# earlgrey register map
Vendor: lowRISC OpenTitan; File version: snapshot-20191101-1-518-g9293d546-dirty
# OpenTitan ![OpenTitan logo](doc/opentitan-logo.png) ## About the project [OpenTitan](https://opentitan.org) is an open source silicon Root of Trust (RoT) project. OpenTitan will make the silicon RoT design and implementation more transparent, trustworthy, and secure for enterprises, platform providers, and chip manufacturers. OpenTitan is administered by [lowRISC CIC](https://www.lowrisc.org) as a collaborative project to produce high quality, open IP for instantiation as a full-featured product. See the the [OpenTitan site](https://opentitan.org/) and [OpenTitan docs](https://docs.opentitan.org) for more information about the project. ## About this repository This repository contains hardware, software and utilities written as part of the OpenTitan project. It is structured as monolithic repository, or "monorepo", where all components live in one repository. It exists to enable collaboration across partners participating in the OpenTitan project. ## Documentation The project contains comprehensive documentation of all IPs and tools. You can either access it [online](https://docs.opentitan.org/) or build it locally by following the steps below. 1. Ensure that you have the required Python modules installed (to be executed in the repository root): ```command $ sudo apt install curl python3 python3-pip $ pip3 install --user -r python-requirements.txt ``` 2. Execute the build script: ```command $ ./util/build_docs.py --preview ``` This compiles the documentation into `./build/d
CPU: RISCV 0, little endian, MPU, no FPU, 0 interrupt priority bits
Registers are 32-bit, read-write, reset 0x0 unless marked. A register's access mark holds for its fields unless they carry their own. Offsets are from the block's base; lines under a group give offsets from that group; [hi:lo] are bit positions; {n}, {i} and the like mark numbered series; 'fields as' and 'values as' point back to an identical list; <NAME> marks a mode.

## Memory map
0x40000000 uart
0x40010000 gpio
0x40020000 spi_device
0x40030000 flash_ctrl
0x40070000 pinmux
0x40080000 rv_timer
0x40090000 rv_plic
0x40110000 aes
0x40120000 hmac
0x40130000 alert_handler
0x40140000 nmi_gen

## Interrupts
0 classa (alert_handler)
0 esc0 (nmi_gen)
0 gpio
0 hmac_done (hmac)
0 prog_empty (flash_ctrl)
0 rxf (spi_device)
0 timer_expired_0_0 (rv_timer)
0 tx_watermark (uart)
1 classb (alert_handler)
1 esc1 (nmi_gen)
1 fifo_full (hmac)
1 prog_lvl (flash_ctrl)
1 rx_watermark (uart)
1 rxlvl (spi_device)
2 classc (alert_handler)
2 esc2 (nmi_gen)
2 hmac_err (hmac)
2 rd_full (flash_ctrl)
2 tx_empty (uart)
2 txlvl (spi_device)
3 classd (alert_handler)
3 esc3 (nmi_gen)
3 rd_lvl (flash_ctrl)
3 rx_overflow (uart)
3 rxerr (spi_device)
4 op_done (flash_ctrl)
4 rx_frame_err (uart)
4 rxoverflow (spi_device)
5 op_error (flash_ctrl)
5 rx_break_err (uart)
5 txunderflow (spi_device)
6 rx_timeout (uart)
7 rx_parity_err (uart)

## rv_timer
Base 0x40080000
0x00 CTRL — Control register
  [0] active0 — If 1, timer operates for TIMER0
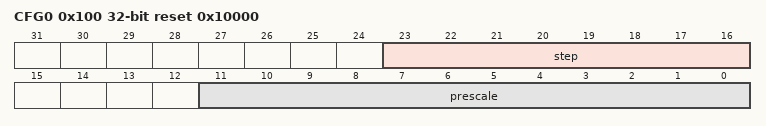
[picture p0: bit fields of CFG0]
0x100 CFG0 reset 0x10000 — Configuration for Hart 0
  [23:16] step — Incremental value for each tick
  [11:0] prescale — Prescaler to generate tick
0x104 TIMER_V_LOWER0 — Timer value Lower
  [31:0] v — Timer value [31:0]
0x108 TIMER_V_UPPER0 — Timer value Upper
  [31:0] v — Timer value [63:32]
0x10C COMPARE_LOWER0_0 reset 0xFFFFFFFF — Timer value Lower
  [31:0] v — Timer compare value [31:0]
0x110 COMPARE_UPPER0_0 reset 0xFFFFFFFF — Timer value Upper
  [31:0] v — Timer compare value [63:32]
0x114 INTR_ENABLE0 — Interrupt Enable
  [0] IE0 — Interrupt Enable for timer for TIMER0
0x118 INTR_STATE0 write-1-clears — Interrupt Status
  [0] IS0 write-1-clears — Interrupt status for timer for TIMER0
0x11C INTR_TEST0 wo reset not defined — Interrupt test register
  [0] T0 — Interrupt test for timer for TIMER0

## rv_plic
Base 0x40090000
0x00 IP group — Interrupt Pending
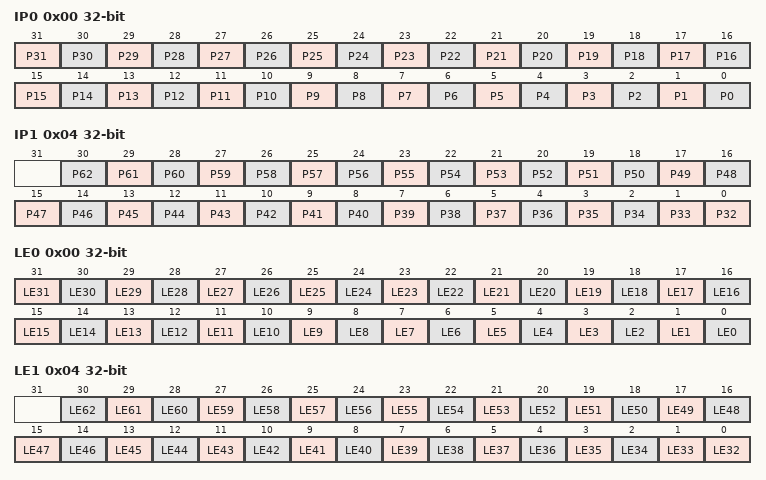
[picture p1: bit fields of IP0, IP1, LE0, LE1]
  0x00 IP0 ro — Interrupt Pending
    [n] P{n} (n=1..31) — for RV_PLIC{n}
    [0] P0 — Interrupt Pending of Source for RV_PLIC0
  0x04 IP1 ro — Interrupt Pending
    [n-32] P{n} (n=33..62) — for RV_PLIC{n}
    [0] P32 — Interrupt Pending of Source for RV_PLIC32
0x08 LE group — Interrupt Source mode. 0: Level, 1: Edge-triggered
  0x00 LE0 — Interrupt Source mode. 0: Level, 1: Edge-triggered
    [n] LE{n} (n=1..31) — for RV_PLIC{n}
    [0] LE0 — L0E1 for RV_PLIC0
  0x04 LE1 — Interrupt Source mode. 0: Level, 1: Edge-triggered
    [n-32] LE{n} (n=33..62) — for RV_PLIC{n}
    [0] LE32 — L0E1 for RV_PLIC32
{0x10+4i} PRIO{i} 2-bit (i=0..62) — Interrupt Source {i} Priority
0x200 IE0 group — Interrupt Enable for Target 0
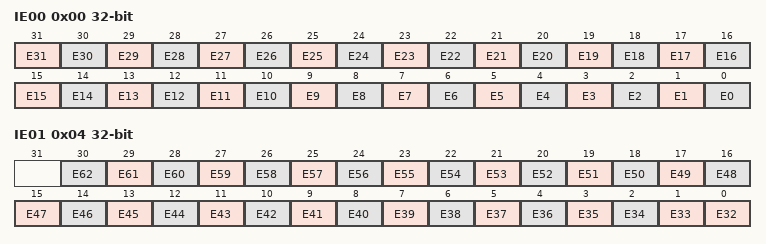
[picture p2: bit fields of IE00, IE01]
  0x00 IE00 — Interrupt Enable for Target 0
    [n] E{n} (n=1..31) — for RV_PLIC{n}
    [0] E0 — Interrupt Enable of Source for RV_PLIC0
  0x04 IE01 — Interrupt Enable for Target 0
    [n-32] E{n} (n=33..62) — for RV_PLIC{n}
    [0] E32 — Interrupt Enable of Source for RV_PLIC32
0x208 THRESHOLD0 2-bit — Threshold of priority for Target 0
0x20C CC0 6-bit — Claim interrupt by read, complete interrupt by write for Target 0. Value read/written is interrupt ID. Reading a value of 0 means no pending interrupts.
0x210 MSIP0 1-bit — msip for Hart 0. Write 1 to here asserts software interrupt for Hart msip_o[0], write 0 to clear.

## Notices in the file
Copyright lowRISC contributors.
SPDX-License-Identifier: Apache-2.0
Licensed under the Apache License, Version 2.0, see LICENSE for details.
